# ATSAML11E15A register map
Vendor: Microchip Technology; Series: SAML11; File version: 0
CPU: CM23 r0p0, selectable endian, MPU, no FPU, 2 interrupt priority bits
Registers are 32-bit, read-write, reset 0x0 unless marked. A register's access mark holds for its fields unless they carry their own. Offsets are from the block's base; [hi:lo] are bit positions; {n}, {i} and the like mark numbered series.

## FREQM — Frequency Meter
Base 0x40002C00; register names take the prefix FREQM_
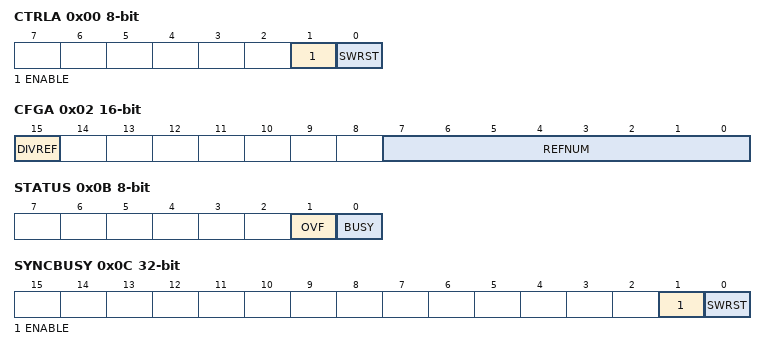
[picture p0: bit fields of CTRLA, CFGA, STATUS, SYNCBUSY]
0x00 CTRLA 8-bit — Control A Register
  [1] ENABLE
  [0] SWRST — Software Reset
0x01 CTRLB 8-bit wo — Control B Register
  [0] START — Start Measurement
0x02 CFGA 16-bit — Config A register
  [15] DIVREF — Divide Reference Clock
  [7:0] REFNUM — Number of Reference Clock Cycles
0x08 INTENCLR 8-bit — Interrupt Enable Clear Register
  [0] DONE — Measurement Done Interrupt Enable
0x09 INTENSET 8-bit — Interrupt Enable Set Register
  [0] DONE — Measurement Done Interrupt Enable
0x0A INTFLAG 8-bit — Interrupt Flag Register
  [0] DONE — Measurement Done
0x0B STATUS 8-bit
  [1] OVF — Sticky Count Value Overflow
  [0] BUSY — FREQM Status
0x0C SYNCBUSY ro — Synchronization Busy Register
  [1] ENABLE
  [0] SWRST — Software Reset
0x10 VALUE ro — Count Value Register
  [23:0] VALUE — Measurement Value

## GCLK — Generic Clock Generator
Base 0x40001C00; register names take the prefix GCLK_
0x00 CTRLA 8-bit — Control
  [0] SWRST — Software Reset
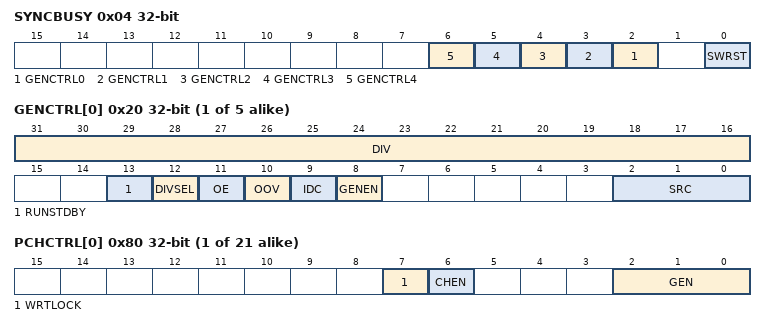
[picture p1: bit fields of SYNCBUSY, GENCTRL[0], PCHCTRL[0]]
0x04 SYNCBUSY ro — Synchronization Busy
  [n+2] GENCTRL{n} (n=0..4) — Generic Clock Generator Control {n} Synchronization Busy bit
  [0] SWRST — Software Reset Synchroniation Busy bit
{0x20+4i} GENCTRL[{i}] (i=0..4) — Generic Clock Generator Control
  [31:16] DIV — Division Factor
  [13] RUNSTDBY — Run in Standby
  [12] DIVSEL — Divide Selection
    0=DIV1 (Divide input directly by divider factor); 1=DIV2 (Divide input by 2^(divider factor+ 1))
  [11] OE — Output Enable
  [10] OOV — Output Off Value
  [9] IDC — Improve Duty Cycle
  [8] GENEN — Generic Clock Generator Enable
  [2:0] SRC — Source Select
    0=XOSC (XOSC oscillator output); 1=GCLKIN (Generator input pad (GCLK_IO)); 2=GCLKGEN1 (Generic clock generator 1 output); 3=OSCULP32K (OSCULP32K oscillator output); 4=XOSC32K (XOSC32K oscillator output); 5=OSC16M (OSC16M oscillator output); 6=DFLLULP (DFLLULP output); 7=FDPLL96M (FDPLL output)
{0x80+4i} PCHCTRL[{i}] (i=0..20) — Peripheral Clock Control
  [7] WRTLOCK — Write Lock
  [6] CHEN — Channel Enable
  [2:0] GEN — Generic Clock Generator
    {v}=GCLK{v} (Generic clock generator {v}) (v=0..4)

## IDAU — Implementation Defined Attribution Unit
Base 0x41000000; register names take the prefix IDAU_
0x01 SECCTRL 8-bit reset 0x3
  [2] RXN — CPU RAM is eXecute Never
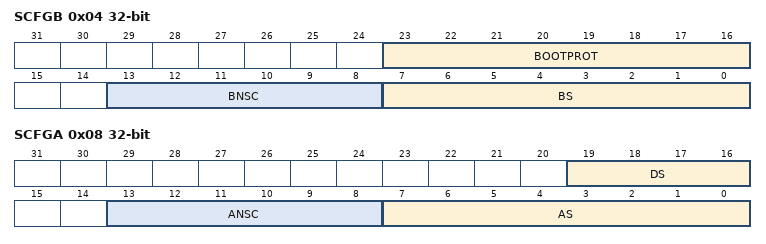
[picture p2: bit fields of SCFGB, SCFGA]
0x04 SCFGB
  [23:16] BOOTPROT — Boot Protection
  [13:8] BNSC — Boot Secure, Non-secure Callable
  [7:0] BS — Boot Secure
0x08 SCFGA
  [19:16] DS — DATAFLASH Data Secure
  [13:8] ANSC — Application Secure, Non-secure Callable
  [7:0] AS — Application Secure
0x0C SCFGR 8-bit
  [6:0] RS — RAM Secure

## MCLK — Main Clock
Base 0x40000800; register names take the prefix MCLK_
0x00 CTRLA 8-bit — Control
  [2] CKSEL — Clock Select
0x01 INTENCLR 8-bit — Interrupt Enable Clear
  [0] CKRDY — Clock Ready Interrupt Enable
0x02 INTENSET 8-bit — Interrupt Enable Set
  [0] CKRDY — Clock Ready Interrupt Enable
0x03 INTFLAG 8-bit reset 0x1 — Interrupt Flag Status and Clear
  [0] CKRDY — Clock Ready
0x04 CPUDIV 8-bit reset 0x1 — CPU Clock Division
  [7:0] CPUDIV — CPU Clock Division Factor
    1=DIV1 (Divide by 1); 2=DIV2 (Divide by 2); 4=DIV4 (Divide by 4); 8=DIV8 (Divide by 8); 16=DIV16 (Divide by 16); 32=DIV32 (Divide by 32); 64=DIV64 (Divide by 64); 128=DIV128 (Divide by 128)
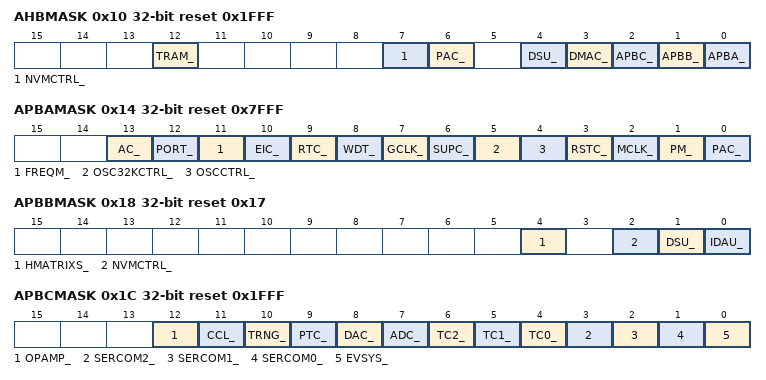
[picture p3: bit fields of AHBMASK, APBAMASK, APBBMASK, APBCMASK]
0x10 AHBMASK reset 0x1FFF
  [12] TRAM_ — TRAM AHB Clock Mask
  [7] NVMCTRL_ — NVMCTRL AHB Clock Mask
  [6] PAC_ — PAC AHB Clock Mask
  [4] DSU_ — DSU AHB Clock Mask
  [3] DMAC_ — DMAC AHB Clock Mask
  [2] APBC_ — AHB-APB Bridge C AHB Clock Mask
  [1] APBB_ — AHB-APB Bridge B AHB Clock Mask
  [0] APBA_ — AHB-APB Bridge A AHB Clock Mask
0x14 APBAMASK reset 0x7FFF
  [13] AC_ — AC APB Clock Enable
  [12] PORT_ — PORT APB Clock Enable
  [11] FREQM_ — FREQM APB Clock Enable
  [10] EIC_ — EIC APB Clock Enable
  [9] RTC_ — RTC APB Clock Enable
  [8] WDT_ — WDT APB Clock Enable
  [7] GCLK_ — GCLK APB Clock Enable
  [6] SUPC_ — SUPC APB Clock Enable
  [5] OSC32KCTRL_ — OSC32KCTRL APB Clock Enable
  [4] OSCCTRL_ — OSCCTRL APB Clock Enable
  [3] RSTC_ — RSTC APB Clock Enable
  [2] MCLK_ — MCLK APB Clock Enable
  [1] PM_ — PM APB Clock Enable
  [0] PAC_ — PAC APB Clock Enable
0x18 APBBMASK reset 0x17
  [4] HMATRIXS_ — HMATRIXHS APBB Clock Enable
  [2] NVMCTRL_ — NVMCTRL APB Clock Enable
  [1] DSU_ — DSU APB Clock Enable
  [0] IDAU_ — IDAU APB Clock Enable
0x1C APBCMASK reset 0x1FFF
  [12] OPAMP_ — OPAMP APB Clock Enable
  [11] CCL_ — CCL APB Clock Enable
  [10] TRNG_ — TRNG APB Clock Enable
  [9] PTC_ — PTC APB Clock Enable
  [8] DAC_ — DAC APB Clock Enable
  [7] ADC_ — ADC APB Clock Enable
  [6] TC2_ — TC2 APB Clock Enable
  [5] TC1_ — TC1 APB Clock Enable
  [4] TC0_ — TC0 APB Clock Enable
  [3] SERCOM2_ — SERCOM2 APB Clock Enable
  [2] SERCOM1_ — SERCOM1 APB Clock Enable
  [1] SERCOM0_ — SERCOM0 APB Clock Enable
  [0] EVSYS_ — EVSYS APB Clock Enable
